# CEC1734_S0_2ZW device description
Architecture: CORTEX-M4; Family: CEC173X; Series: CEC
Registers are 32-bit, read-write, reset 0x0 unless marked. A register's access mark holds for its fields unless they carry their own. Offsets are from the block's base; [hi:lo] are bit positions; lines under a group give offsets from that group; {n}, {i} and the like mark numbered series; 'fields as' and 'values as' point back to an identical list.

## ECIA — The ECIA works in conjunction with the processor interrupt interface to handle hardware interrupts andd exceptions.
Instances: ECIA 0x4000E000
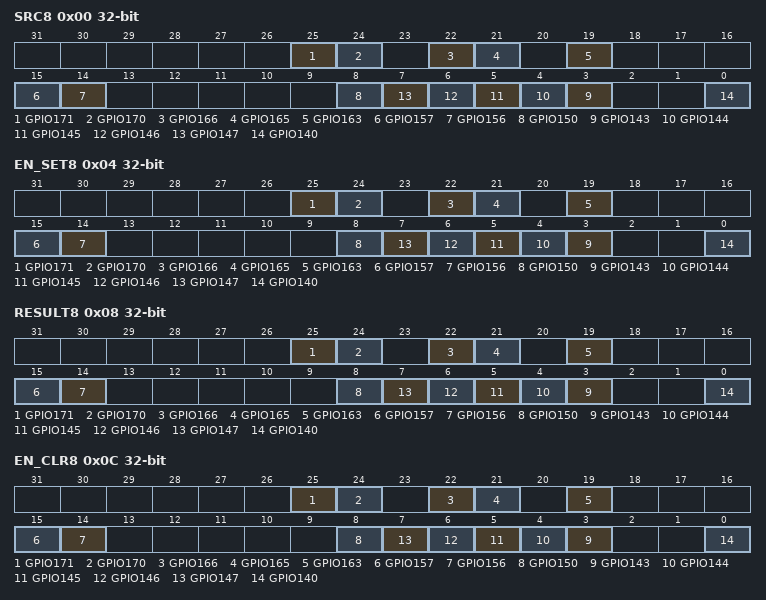
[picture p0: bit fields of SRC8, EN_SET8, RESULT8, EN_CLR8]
0x00 SRC8 — GIRQ8 SOURCE
  [25] GPIO171, [24] GPIO170, [22] GPIO166, [21] GPIO165, [19] GPIO163, [15] GPIO157, [14] GPIO156, [8] GPIO150, [n-140] GPIO{n} (n=143..147), [0] GPIO140
0x04 EN_SET8 (atomic set of EN_SET) — GIRQ8 ENABLE SET
  fields as SRC8
0x08 RESULT8 ro — GIRQ8 RESULT
  fields as SRC8
0x0C EN_CLR8 (atomic clear of EN_CLR) — GIRQ8 ENABLE CLEAR
  fields as SRC8
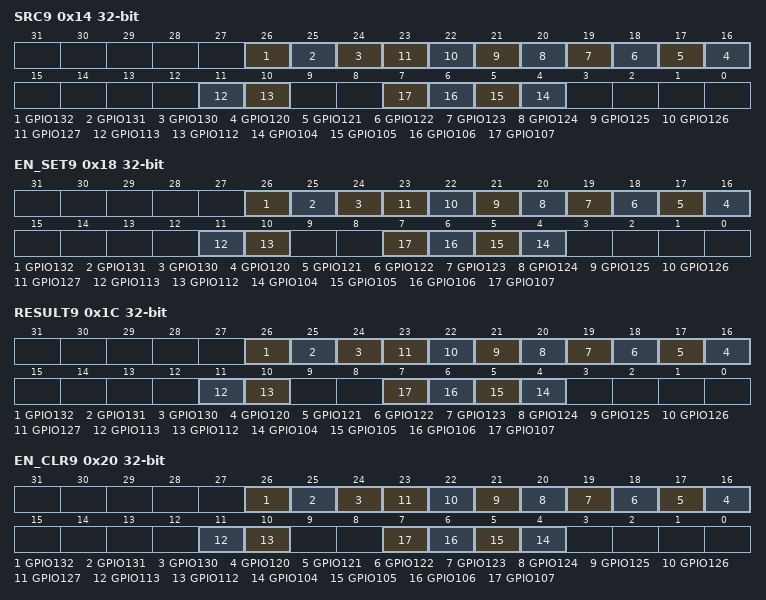
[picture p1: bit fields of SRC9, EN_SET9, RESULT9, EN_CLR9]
0x14 SRC9 — GIRQ9 SOURCE
  [26] GPIO132, [25] GPIO131, [24] GPIO130, [n-104] GPIO{n} (n=120..127), [11] GPIO113, [10] GPIO112, [n-100] GPIO{n} (n=104..107)
0x18 EN_SET9 (atomic set of EN_SET) — GIRQ9 ENABLE SET
  fields as SRC9
0x1C RESULT9 ro — GIRQ9 RESULT
  fields as SRC9
0x20 EN_CLR9 (atomic clear of EN_CLR) — GIRQ9 ENABLE CLEAR
  fields as SRC9
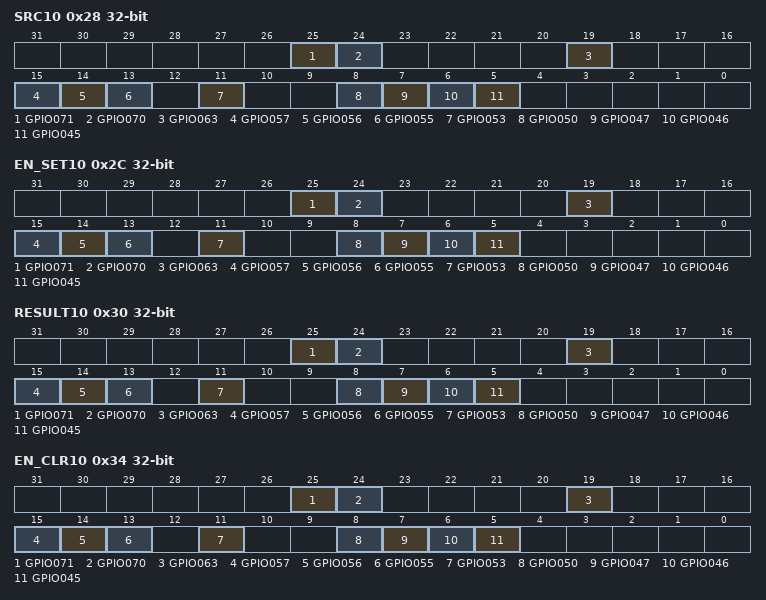
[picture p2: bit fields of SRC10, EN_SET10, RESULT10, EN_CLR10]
0x28 SRC10 — GIRQ10 SOURCE
  [25] GPIO071
  [24] GPIO070
  [19] GPIO063 — GPIO 060
  [15] GPIO057
  [14] GPIO056
  [13] GPIO055
  [11] GPIO053
  [8] GPIO050
  [7] GPIO047
  [6] GPIO046
  [5] GPIO045
0x2C EN_SET10 (atomic set of EN_SET) — GIRQ10 ENABLE SET
  fields as SRC10
0x30 RESULT10 ro — GIRQ10 RESULT
  fields as SRC10
0x34 EN_CLR10 (atomic clear of EN_CLR) — GIRQ10 ENABLE CLEAR
  fields as SRC10
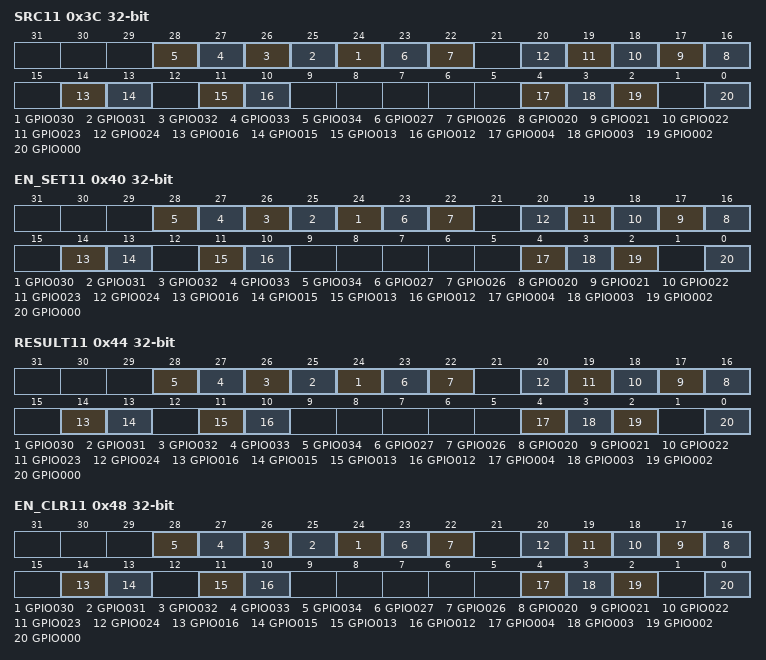
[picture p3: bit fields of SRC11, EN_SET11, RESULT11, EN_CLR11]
0x3C SRC11 — GIRQ11 SOURCE
  [n-6] GPIO{n:03} (n=30..34), [23] GPIO027, [22] GPIO026, [n-4] GPIO{n:03} (n=20..24), [14] GPIO016, [13] GPIO015, [11] GPIO013, [10] GPIO012, [4] GPIO004, [3] GPIO003, [2] GPIO002, [0] GPIO000
0x40 EN_SET11 (atomic set of EN_SET) — GIRQ11 ENABLE SET
  fields as SRC11
0x44 RESULT11 ro — GIRQ11 RESULT
  fields as SRC11
0x48 EN_CLR11 (atomic clear of EN_CLR) — GIRQ11 ENABLE CLEAR
  fields as SRC11
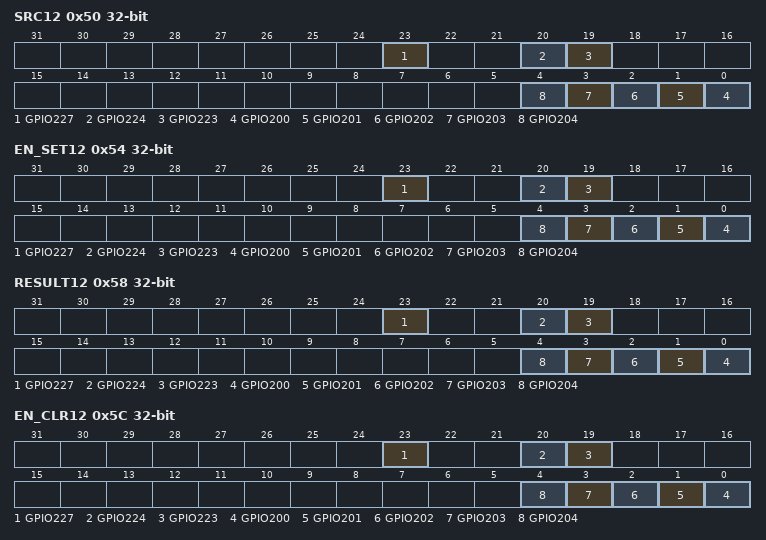
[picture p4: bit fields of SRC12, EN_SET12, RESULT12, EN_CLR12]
0x50 SRC12 — GIRQ12 SOURCE
  [23] GPIO227, [20] GPIO224, [19] GPIO223, [n-200] GPIO{n} (n=200..204)
0x54 EN_SET12 (atomic set of EN_SET) — GIRQ12 ENABLE SET
  fields as SRC12
0x58 RESULT12 ro — GIRQ12 RESULT
  fields as SRC12
0x5C EN_CLR12 (atomic clear of EN_CLR) — GIRQ12 ENABLE CLEAR
  fields as SRC12
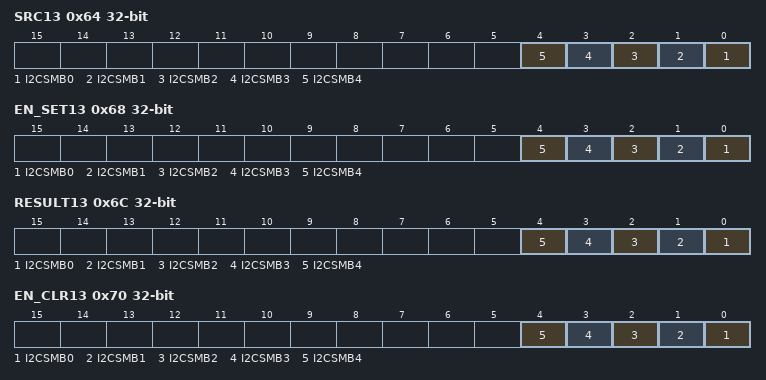
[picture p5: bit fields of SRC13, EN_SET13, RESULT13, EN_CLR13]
0x64 SRC13 — GIRQ13 SOURCE
  [n] I2CSMB{n} (n=0..4)
0x68 EN_SET13 (atomic set of EN_SET) — GIRQ13 ENABLE SET
  [n] I2CSMB{n} (n=0..4)
0x6C RESULT13 ro — GIRQ13 RESULT
  [n] I2CSMB{n} (n=0..4)
0x70 EN_CLR13 (atomic clear of EN_CLR) — GIRQ13 ENABLE CLEAR
  [n] I2CSMB{n} (n=0..4)
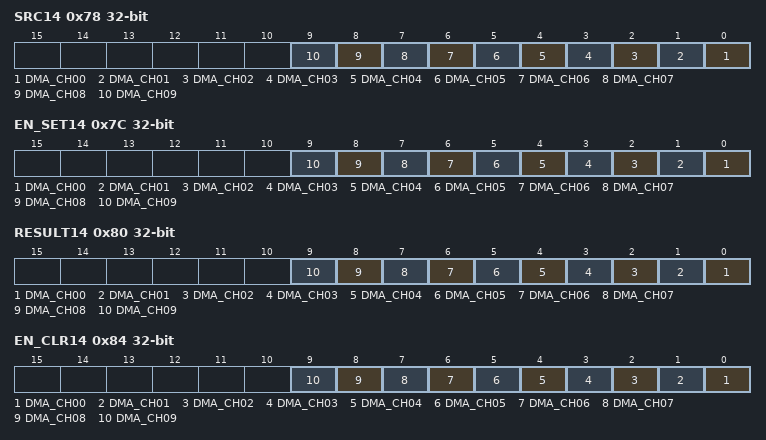
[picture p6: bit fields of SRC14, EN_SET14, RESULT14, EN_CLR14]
0x78 SRC14 — GIRQ14 SOURCE
  [n] DMA_CH{n:02} (n=0..9)
0x7C EN_SET14 (atomic set of EN_SET) — GIRQ14 ENABLE SET
  [n] DMA_CH{n:02} (n=0..9)
0x80 RESULT14 ro — GIRQ14 RESULT
  [n] DMA_CH{n:02} (n=0..9)
0x84 EN_CLR14 (atomic clear of EN_CLR) — GIRQ14 ENABLE CLEAR
  [n] DMA_CH{n:02} (n=0..9)
0x8C SRC15 — GIRQ15 SOURCE
  [0] UART0
0x90 EN_SET15 (atomic set of EN_SET) — GIRQ15 ENABLE SET
  [0] UART0
0x94 RESULT15 ro — GIRQ15 RESULT
  [0] UART0
0x98 EN_CLR15 (atomic clear of EN_CLR) — GIRQ15 ENABLE CLEAR
  [0] UART0
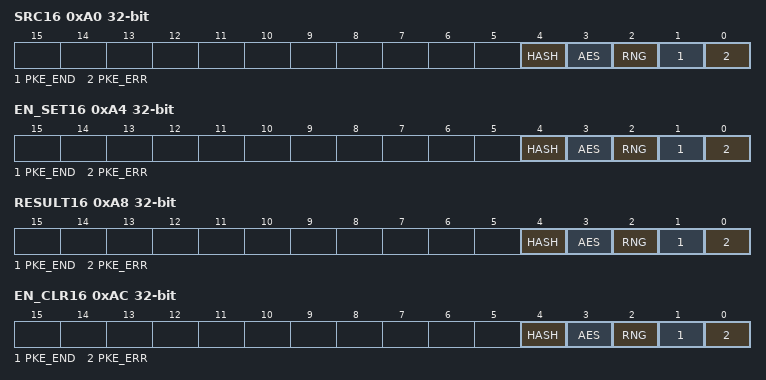
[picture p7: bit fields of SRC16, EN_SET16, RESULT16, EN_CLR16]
0xA0 SRC16 — GIRQ16 SOURCE
  [4] HASH, [3] AES, [2] RNG, [1] PKE_END, [0] PKE_ERR
0xA4 EN_SET16 (atomic set of EN_SET) — GIRQ16 ENABLE SET
  [4] HASH, [3] AES, [2] RNG, [1] PKE_END, [0] PKE_ERR
0xA8 RESULT16 ro — GIRQ16 RESULT
  [4] HASH, [3] AES, [2] RNG, [1] PKE_END, [0] PKE_ERR
0xAC EN_CLR16 (atomic clear of EN_CLR) — GIRQ16 ENABLE CLEAR
  [4] HASH, [3] AES, [2] RNG, [1] PKE_END, [0] PKE_ERR
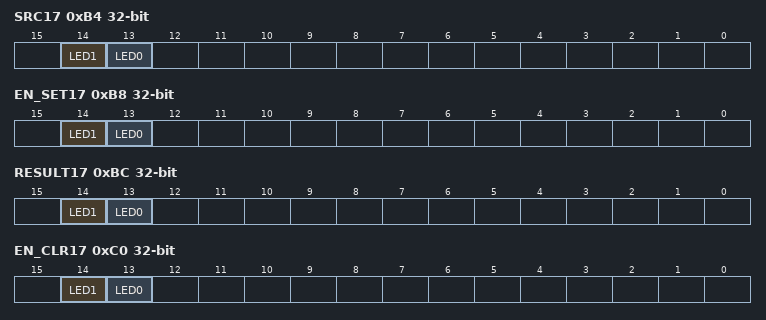
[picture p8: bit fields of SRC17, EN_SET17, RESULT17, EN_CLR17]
0xB4 SRC17 — GIRQ17 SOURCE
  [14] LED1 — Breating LED1
  [13] LED0 — Breating LED0
0xB8 EN_SET17 (atomic set of EN_SET) — GIRQ17 ENABLE SET
  [14] LED1 — Breating LED1
  [13] LED0 — Breating LED0
0xBC RESULT17 ro — GIRQ17 RESULT
  [14] LED1 — Breating LED1
  [13] LED0 — Breating LED0
0xC0 EN_CLR17 (atomic clear of EN_CLR) — GIRQ17 ENABLE CLEAR
  [14] LED1 — Breating LED1
  [13] LED0 — Breating LED0
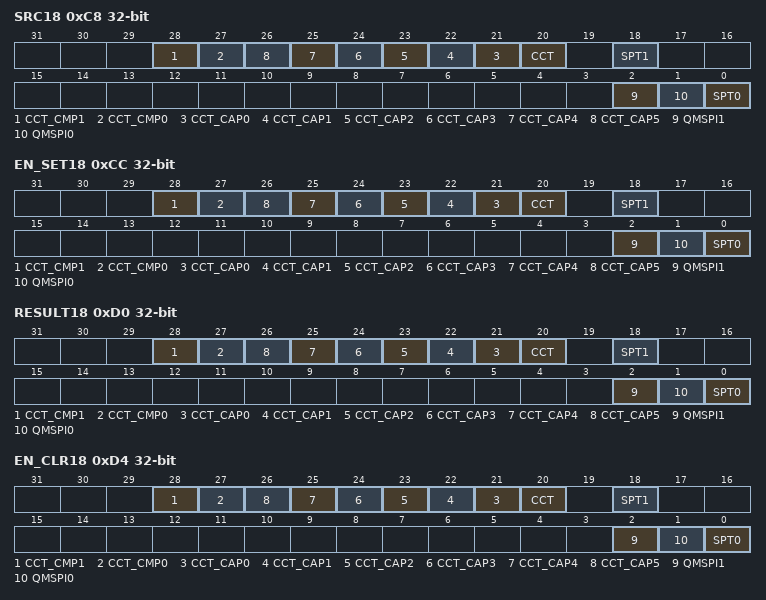
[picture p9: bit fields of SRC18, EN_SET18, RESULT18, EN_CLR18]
0xC8 SRC18 — GIRQ18 SOURCE
  [28] CCT_CMP1, [27] CCT_CMP0, [n+21] CCT_CAP{n} (n=0..5), [20] CCT, [18] SPT1, [2] QMSPI1, [1] QMSPI0, [0] SPT0
0xCC EN_SET18 (atomic set of EN_SET) — GIRQ18 ENABLE SET
  fields as SRC18
0xD0 RESULT18 ro — GIRQ18 RESULT
  fields as SRC18
0xD4 EN_CLR18 (atomic clear of EN_CLR) — GIRQ18 ENABLE CLEAR
  fields as SRC18
0xDC SRC19 — GIRQ19 SOURCE
0xE0 EN_SET19 (atomic set of EN_SET) — GIRQ19 ENABLE SET
0xE4 RESULT19 ro — GIRQ19 RESULT
0xE8 EN_CLR19 (atomic clear of EN_CLR) — GIRQ19 ENABLE CLEAR
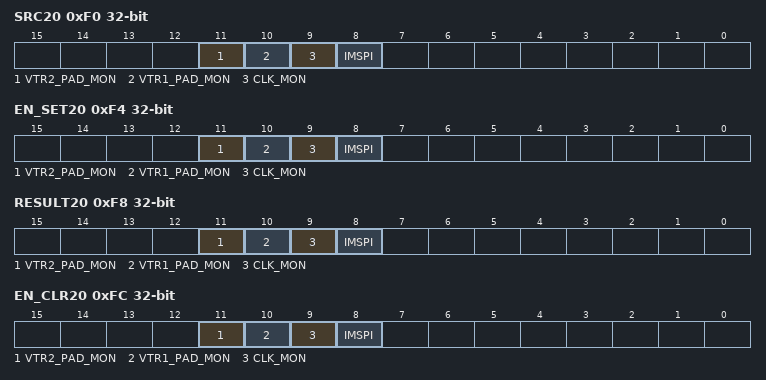
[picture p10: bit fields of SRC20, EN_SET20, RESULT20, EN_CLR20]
0xF0 SRC20 — GIRQ20 SOURCE
  [11] VTR2_PAD_MON, [10] VTR1_PAD_MON, [9] CLK_MON, [8] IMSPI
0xF4 EN_SET20 (atomic set of EN_SET) — GIRQ20 ENABLE SET
  [11] VTR2_PAD_MON, [10] VTR1_PAD_MON, [9] CLK_MON, [8] IMSPI
0xF8 RESULT20 ro — GIRQ20 RESULT
  [11] VTR2_PAD_MON, [10] VTR1_PAD_MON, [9] CLK_MON, [8] IMSPI
0xFC EN_CLR20 (atomic clear of EN_CLR) — GIRQ20 ENABLE CLEAR
  [11] VTR2_PAD_MON, [10] VTR1_PAD_MON, [9] CLK_MON, [8] IMSPI
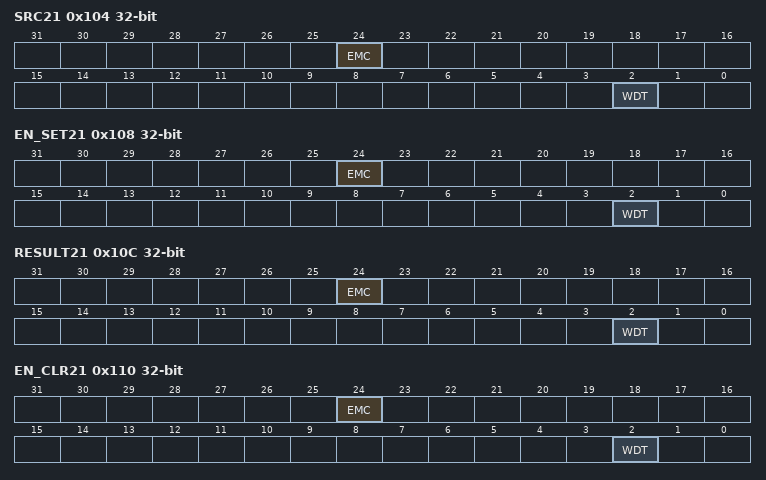
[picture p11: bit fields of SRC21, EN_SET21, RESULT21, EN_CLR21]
0x104 SRC21 — GIRQ21 SOURCE
  [24] EMC, [2] WDT
0x108 EN_SET21 (atomic set of EN_SET) — GIRQ21 ENABLE SET
  [24] EMC, [2] WDT
0x10C RESULT21 ro — GIRQ21 RESULT
  [24] EMC, [2] WDT
0x110 EN_CLR21 (atomic clear of EN_CLR) — GIRQ21 ENABLE CLEAR
  [24] EMC, [2] WDT
0x118 SRC22 — GIRQ22 SOURCE
0x11C EN_SET22 (atomic set of EN_SET) — GIRQ22 ENABLE SET
0x120 RESULT22 ro — GIRQ22 RESULT
0x124 EN_CLR22 (atomic clear of EN_CLR) — GIRQ22 ENABLE CLEAR
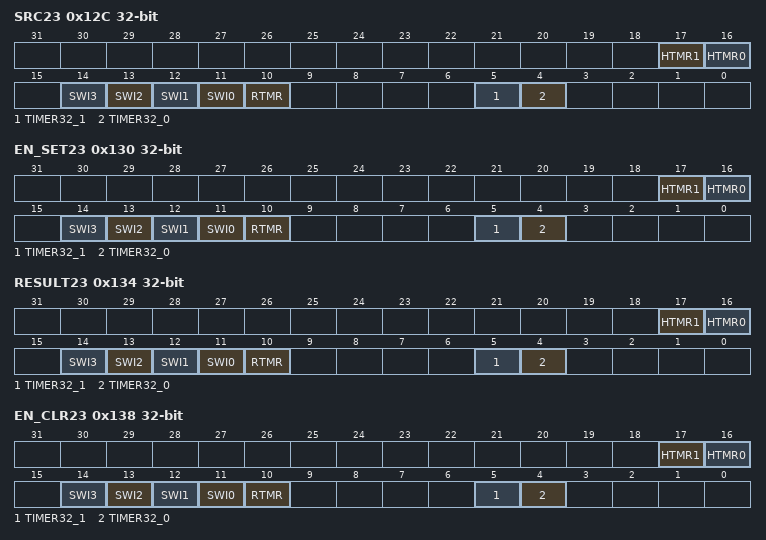
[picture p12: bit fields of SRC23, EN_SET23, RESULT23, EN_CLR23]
0x12C SRC23 — GIRQ23 SOURCE
  [17] HTMR1, [16] HTMR0, [n+11] SWI{n} (n=0..3), [10] RTMR, [5] TIMER32_1, [4] TIMER32_0
0x130 EN_SET23 (atomic set of EN_SET) — GIRQ23 ENABLE SET
  fields as SRC23
0x134 RESULT23 ro — GIRQ23 RESULT
  fields as SRC23
0x138 EN_CLR23 (atomic clear of EN_CLR) — GIRQ23 ENABLE CLEAR
  fields as SRC23
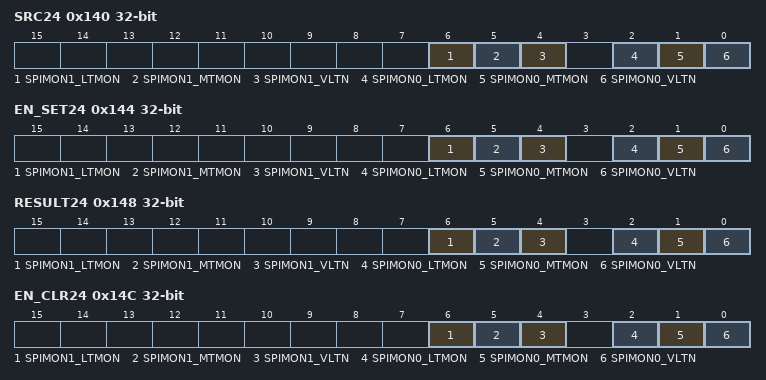
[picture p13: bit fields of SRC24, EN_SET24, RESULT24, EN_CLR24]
0x140 SRC24 — GIRQ24 SOURCE
  [6] SPIMON1_LTMON, [5] SPIMON1_MTMON, [4] SPIMON1_VLTN, [2] SPIMON0_LTMON, [1] SPIMON0_MTMON, [0] SPIMON0_VLTN
0x144 EN_SET24 (atomic set of EN_SET) — GIRQ24 ENABLE SET
  fields as SRC24
0x148 RESULT24 ro — GIRQ24 RESULT
  fields as SRC24
0x14C EN_CLR24 (atomic clear of EN_CLR) — GIRQ24 ENABLE CLEAR
  fields as SRC24
0x154 SRC25 — GIRQ25 SOURCE
0x158 EN_SET25 (atomic set of EN_SET) — GIRQ25 ENABLE SET
0x15C RESULT25 ro — GIRQ25 RESULT
0x160 EN_CLR25 (atomic clear of EN_CLR) — GIRQ25 ENABLE CLEAR
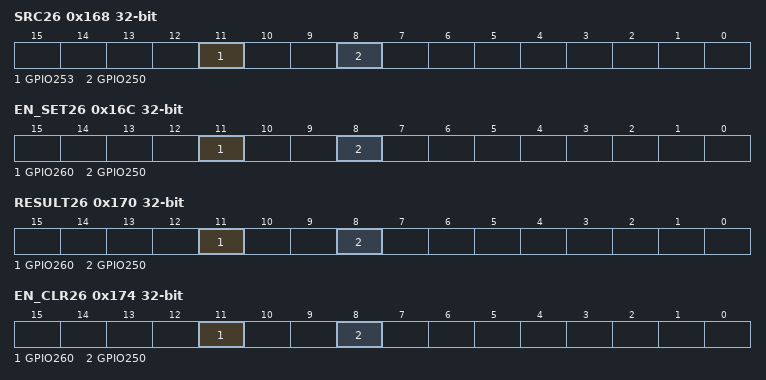
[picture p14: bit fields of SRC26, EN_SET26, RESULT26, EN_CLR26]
0x168 SRC26 — GIRQ26 SOURCE
  [11] GPIO253, [8] GPIO250
0x16C EN_SET26 (atomic set of EN_SET) — GIRQ26 ENABLE SET
  [11] GPIO260, [8] GPIO250
0x170 RESULT26 ro — GIRQ26 RESULT
  [11] GPIO260, [8] GPIO250
0x174 EN_CLR26 (atomic clear of EN_CLR) — GIRQ26 ENABLE CLEAR
  [11] GPIO260, [8] GPIO250
0x200 BLK_EN_SET (atomic set of BLOCK_ENABLE_SET) — Block Enable Set Register
  [30:0] VTOR_EN_SET — Each GIRQx bit can be individually enabled to assert an interrupt event. Reads always return the current value of the internal GIRQX_ENABLE bit. The state of the GIRQX_ENABLE bit is determined by the corresponding GIRQX_ENABLE_SET bit and the GIRQX_ENABLE_CLEAR bit. (0=disabled, 1=enabled) (R/WS) 1=Interrupts in the GIRQx Source Register may be enabled 0=No effect.
0x204 BLK_EN_CLR — Block Enable Clear Register.
  [30:0] VTOR_EN_CLR — Each GIRQx bit can be individually disabled to inhibit an interrupt event. Reads always return the current value of the internal GIRQX_ENABLE bit. The state of the GIRQX_ENABLE bit is determined by the corresponding GIRQX_ENABLE_SET bit and the GIRQX_ENABLE_CLEAR bit. (0=disabled, 1=enabled) (R/WC) 1=All interrupts in the GIRQx Source Register are disabled 0=No effect.
0x208 BLK_IRQ_VTOR ro — Block IRQ Vector Register
  [24:0] VTOR — Each bit in this field reports the status of the group GIRQ interrupt assertion to the NVIC. If the GIRQx interrupt is disabled as a group, by the Block Enable Clear Register, then the corresponding bit will be '0'b and no interrupt will be asserted.
